# cs register map
Vendor: Texas Instruments
Peripheral module from a debugger description file (folder MSP432).
Registers are 32-bit, read-write, no defined reset value unless marked. A register's access mark holds for its fields unless they carry their own. Offsets are as the file gives them; lines under a group give offsets from that group; [hi:lo] are bit positions; {n}, {i} and the like mark numbered series; 'fields as' and 'values as' point back to an identical list; <NAME> marks a mode.

## CS
0x00 KEY
  [15:0] KEY — Write CSKEY = xxxx_695Ah to unlock CSCTL0, CSCTL1, CSCTL2, CSCT
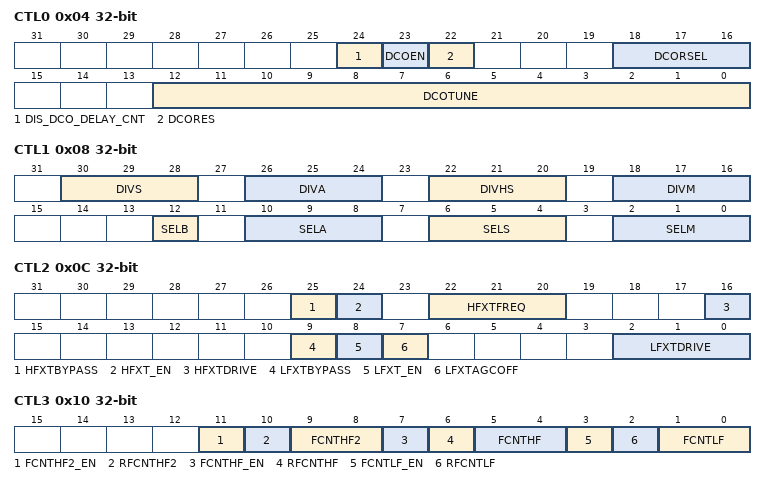
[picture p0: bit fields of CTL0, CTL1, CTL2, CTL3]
0x04 CTL0 — Control 0 Register
  [24] DIS_DCO_DELAY_CNT — Setting this bit disabes the DCO settling counter value
    0=DIS_DCO_DELAY_CNT__0 (DCO Settling delay counter is enabled); 1=DIS_DCO_DELAY_CNT__1 (DCO setlling delay counter disabled)
  [23] DCOEN — Enables the DCO oscillator regardless if used as a clock resour
    0=DCOEN__0 (DCO is on if it is used as a source for MCLK, HSMCLK , or SMCLK); 1=DCOEN__1 (DCO is on)
  [22] DCORES — Enables the DCO external resistor mode.
    0=DCORES__0 (Internal resistor mode); 1=DCORES__1 (External resistor mode)
  [18:16] DCORSEL — DCO frequency range select
    0=DCORSEL__0 (Nominal DCO Frequency Range (MHz): 1 to 2); 1=DCORSEL__1 (Nominal DCO Frequency Range (MHz): 2 to 4); 2=DCORSEL__2 (Nominal DCO Frequency Range (MHz): 4 to 8); 3=DCORSEL__3 (Nominal DCO Frequency Range (MHz): 8 to 16); 4=DCORSEL__4 (Nominal DCO Frequency Range (MHz): 16 to 32); 5=DCORSEL__5 (Nominal DCO Frequency Range (MHz): 32 to 64)
  [12:0] DCOTUNE — DCO frequency tuning select
0x08 CTL1 — Control 1 Register
  [30:28] DIVS — SMCLK source divider.
    0=DIVS__0 (f(SMCLK)/1); 1=DIVS__1 (f(SMCLK)/2); 2=DIVS__2 (f(SMCLK)/4); 3=DIVS__3 (f(SMCLK)/8); 4=DIVS__4 (f(SMCLK)/16); 5=DIVS__5 (f(SMCLK)/32); 6=DIVS__6 (f(SMCLK)/64); 7=DIVS__7 (f(SMCLK)/128)
  [26:24] DIVA — ACLK source divider.
    0=DIVA__0 (f(ACLK)/1); 1=DIVA__1 (f(ACLK)/2); 2=DIVA__2 (f(ACLK)/4); 3=DIVA__3 (f(ACLK)/8); 4=DIVA__4 (f(ACLK)/16); 5=DIVA__5 (f(ACLK)/32); 6=DIVA__6 (f(ACLK)/64); 7=DIVA__7 (f(ACLK)/128)
  [22:20] DIVHS — HSMCLK source divider.
    0=DIVHS__0 (f(HSMCLK)/1); 1=DIVHS__1 (f(HSMCLK)/2); 2=DIVHS__2 (f(HSMCLK)/4); 3=DIVHS__3 (f(HSMCLK)/8); 4=DIVHS__4 (f(HSMCLK)/16); 5=DIVHS__5 (f(HSMCLK)/32); 6=DIVHS__6 (f(HSMCLK)/64); 7=DIVHS__7 (f(HSMCLK)/128)
  [18:16] DIVM — MCLK source divider.
    0=DIVM__0 (f(MCLK)/1); 1=DIVM__1 (f(MCLK)/2); 2=DIVM__2 (f(MCLK)/4); 3=DIVM__3 (f(MCLK)/8); 4=DIVM__4 (f(MCLK)/16); 5=DIVM__5 (f(MCLK)/32); 6=DIVM__6 (f(MCLK)/64); 7=DIVM__7 (f(MCLK)/128)
  [12] SELB — Selects the BCLK source.
    0=SELB__0 (LFXTCLK); 1=SELB__1 (REFOCLK)
  [10:8] SELA — Selects the ACLK source.
    0=SELA__0 (when LFXT available, otherwise REFOCLK); 1=SELA__1; 2=SELA__2; {v}=SELA__{v} (for future use) (v=3..7)
  [6:4] SELS — Selects the SMCLK and HSMCLK source.
    0=SELS__0 (when LFXT available, otherwise REFOCLK); {v}=SELS__{v} (v=1..4); 5=SELS__5 (when HFXT available, otherwise DCOCLK); 6=SELS__6 (when HFXT2 available, otherwise DCOCLK); 7=SELS__7 (for furture use)
  [2:0] SELM — Selects the MCLK source.
    0=SELM__0 (when LFXT available, otherwise REFOCLK); {v}=SELM__{v} (v=1..4); 5=SELM__5 (when HFXT available, otherwise DCOCLK); 6=SELM__6 (when HFXT2 available, otherwise DCOCLK); 7=SELM__7 (for future use)
0x0C CTL2 — Control 2 Register
  [25] HFXTBYPASS — HFXT bypass select.
    0=HFXTBYPASS__0 (HFXT sourced by external crystal.); 1=HFXTBYPASS__1 (HFXT sourced by external square wave.)
  [24] HFXT_EN — Turns on the HFXT oscillator regardless if used as a clock reso
    0=HFXT_EN__0 (HFXT is on if it is used as a source for MCLK, HSMCLK , or SMCL); 1=HFXT_EN__1 (HFXT is on if HFXT is selected via the port selection and HFXT)
  [22:20] HFXTFREQ — The HFXT frequency selection
    0=HFXTFREQ__0 (1 MHz to 4 MHz); 1=HFXTFREQ__1 (>4 MHz to 8 MHz); 2=HFXTFREQ__2 (>8 MHz to 16 MHz); 3=HFXTFREQ__3 (>16 MHz to 24 MHz); 4=HFXTFREQ__4 (>24 MHz to 32 MHz); 5=HFXTFREQ__5 (>32 MHz to 40 MHz); 6=HFXTFREQ__6 (>40 MHz to 48 MHz)
  [16] HFXTDRIVE — HFXT oscillator drive selection
    0=HFXTDRIVE__0 (To be used for HFXTFREQ setting 000b); 1=HFXTDRIVE__1 (To be used for HFXTFREQ settings 001b to 111b)
  [9] LFXTBYPASS — LFXT bypass select.
    0=LFXTBYPASS__0 (LFXT sourced by external crystal.); 1=LFXTBYPASS__1 (LFXT sourced by external square wave.)
  [8] LFXT_EN — Turns on the LFXT oscillator regardless if used as a clock reso
    0=LFXT_EN__0 (LFXT is on if it is used as a source for ACLK, MCLK, HSMCLK , o); 1=LFXT_EN__1 (LFXT is on if LFXT is selected via the port selection and LFXT)
  [7] LFXTAGCOFF
    0=LFXTAGCOFF__0 (AGC enabled.); 1=LFXTAGCOFF__1 (AGC disabled.)
  [2:0] LFXTDRIVE — The LFXT oscillator current can be adjusted to its drive needs
    0=LFXTDRIVE__0 (Lowest current consumption.); {v}=LFXTDRIVE__{v} (Increased drive strength LFXT oscillator.) (v=1..6); 7=LFXTDRIVE__7 (Maximum drive strength LFXT oscillator.)
0x10 CTL3 — Control 3 Register
  [11] FCNTHF2_EN — Enable start fault counter for HFXT2
    0=FCNTHF2_EN__0 (Startup fault counter disabled. Counter is cleared.); 1=FCNTHF2_EN__1 (Startup fault counter enabled.)
  [10] RFCNTHF2 — Reset start fault counter for HFXT2
    0=RFCNTHF2__0 (Not applicable. Always reads as zero due to self clearing.); 1=RFCNTHF2__1 (Restarts the counter immediately.)
  [9:8] FCNTHF2 — Start flag counter for HFXT2
    0=FCNTHF2__0 (2048 cycles); 1=FCNTHF2__1 (4096 cycles); 2=FCNTHF2__2 (8192 cycles); 3=FCNTHF2__3 (16384 cycles)
  [7] FCNTHF_EN — Enable start fault counter for HFXT
    0=FCNTHF_EN__0 (Startup fault counter disabled. Counter is cleared.); 1=FCNTHF_EN__1 (Startup fault counter enabled.)
  [6] RFCNTHF — Reset start fault counter for HFXT
    0=RFCNTHF__0 (Not applicable. Always reads as zero due to self clearing.); 1=RFCNTHF__1 (Restarts the counter immediately.)
  [5:4] FCNTHF — Start flag counter for HFXT
    0=FCNTHF__0 (2048 cycles); 1=FCNTHF__1 (4096 cycles); 2=FCNTHF__2 (8192 cycles); 3=FCNTHF__3 (16384 cycles)
  [3] FCNTLF_EN — Enable start fault counter for LFXT
    0=FCNTLF_EN__0 (Startup fault counter disabled. Counter is cleared.); 1=FCNTLF_EN__1 (Startup fault counter enabled.)
  [2] RFCNTLF — Reset start fault counter for LFXT
    0=RFCNTLF__0 (Not applicable. Always reads as zero due to self clearing.); 1=RFCNTLF__1 (Restarts the counter immediately.)
  [1:0] FCNTLF — Start flag counter for LFXT
    0=FCNTLF__0 (4096 cycles); 1=FCNTLF__1 (8192 cycles); 2=FCNTLF__2 (16384 cycles); 3=FCNTLF__3 (32768 cycles)
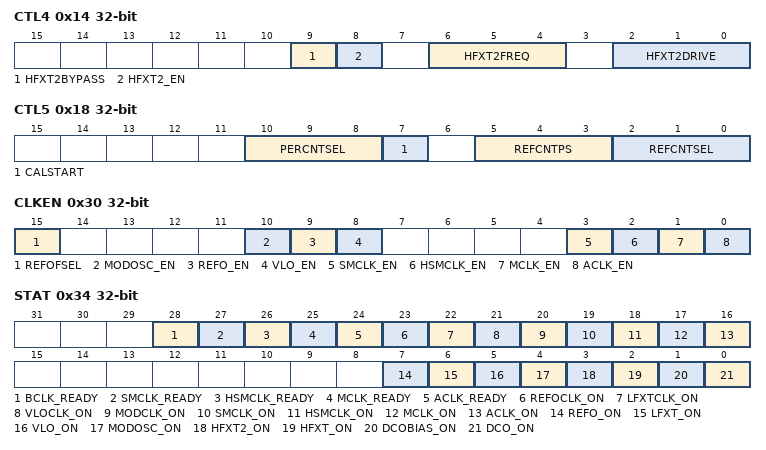
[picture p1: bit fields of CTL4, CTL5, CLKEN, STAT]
0x14 CTL4 — Control 4 Register
  [9] HFXT2BYPASS — HFXT2 bypass select
  [8] HFXT2_EN — Turns on the HFXT2 oscillator regardless if used as a clock res
  [6:4] HFXT2FREQ — The HFXT2 frequency selection
  [2:0] HFXT2DRIVE — The HFXT2 oscillator current can be adjusted to its drive needs
    0=HFXT2DRIVE__0 (Lowest current consumption); {v}=HFXT2DRIVE__{v} (Increased drive strength HFXT2 oscillator) (v=1..6); 7=HFXT2DRIVE__7 (Maximum drive strength HFXT2 oscillator)
0x18 CTL5 — Control 5 Register
  [10:8] PERCNTSEL — Period counter source select
  [7] CALSTART — Start clock calibration counters
  [5:3] REFCNTPS — Reference clock prescaler 000b = /1 001b = /16 010b = /32 0
  [2:0] REFCNTSEL — Reference counter source select
0x1C CTL6 — Control 6 Register
  [15:0] PERCNT — Calibration period counter. Read only.
0x20 CTL7 — Control 7 Register
  [15:0] REFCNT — Calibration reference period counter.
0x30 CLKEN — Clock Enable Register
  [15] REFOFSEL — Selects REFO nominal frequency.
    0=REFOFSEL__0 (32 kHz); 1=REFOFSEL__1 (128 kHz)
  [10] MODOSC_EN — Turns on the MODOSC oscillator regardless if used as a clock re
    0=MODOSC_EN__0 (MODOSC is on only if it is used as a source for ACLK, MCLK, HSM); 1=MODOSC_EN__1 (MODOSC is on)
  [9] REFO_EN — Turns on the REFO oscillator regardless if used as a clock reso
    0=REFO_EN__0 (REFO is on only if it is used as a source for ACLK, MCLK, HSMCL); 1=REFO_EN__1 (REFO is on)
  [8] VLO_EN — Turns on the VLO oscillator regardless if used as a clock resou
    0=VLO_EN__0 (VLO is on only if it is used as a source for ACLK, MCLK, HSMCLK); 1=VLO_EN__1 (VLO is on)
  [3] SMCLK_EN — SMCLK system clock conditional request enable.
    0=SMCLK_EN__0 (SMCLK disabled regardless of conditional clock requests.); 1=SMCLK_EN__1 (SMCLK enabled based on any conditional clock requests)
  [2] HSMCLK_EN — HSMCLK system clock conditional request enable.
    0=HSMCLK_EN__0 (HSMCLK disabled regardless of conditional clock requests); 1=HSMCLK_EN__1 (HSMCLK enabled based on any conditional clock requests)
  [1] MCLK_EN — MCLK system clock conditional request enable
    0=MCLK_EN__0 (MCLK disabled regardless of conditional clock requests); 1=MCLK_EN__1 (MCLK enabled based on any conditional clock requests)
  [0] ACLK_EN — ACLK system clock conditional request enable.
    0=ACLK_EN__0 (ACLK disabled regardless of conditional clock requests); 1=ACLK_EN__1 (ACLK enabled based on any conditional clock requests)
0x34 STAT — Status Register
  [28] BCLK_READY — BCLK Ready status
    0=BCLK_READY__0 (Not ready); 1=BCLK_READY__1 (Ready)
  [27] SMCLK_READY — SMCLK Ready status
    0=SMCLK_READY__0 (Not ready); 1=SMCLK_READY__1 (Ready)
  [26] HSMCLK_READY — HSMCLK Ready status
    0=HSMCLK_READY__0 (Not ready); 1=HSMCLK_READY__1 (Ready)
  [25] MCLK_READY — MCLK Ready status
    0=MCLK_READY__0 (Not ready); 1=MCLK_READY__1 (Ready)
  [24] ACLK_READY — ACLK Ready status
    0=ACLK_READY__0 (Not ready); 1=ACLK_READY__1 (Ready)
  [23] REFOCLK_ON — REFOCLK system clock status
    0=REFOCLK_ON__0 (Inactive); 1=REFOCLK_ON__1 (Active)
  [22] LFXTCLK_ON — LFXTCLK system clock status
    0=LFXTCLK_ON__0 (Inactive); 1=LFXTCLK_ON__1 (Active)
  [21] VLOCLK_ON — VLOCLK system clock status
    0=VLOCLK_ON__0 (Inactive); 1=VLOCLK_ON__1 (Active)
  [20] MODCLK_ON — MODCLK system clock status
    0=MODCLK_ON__0 (Inactive); 1=MODCLK_ON__1 (Active)
  [19] SMCLK_ON — SMCLK system clock status
    0=SMCLK_ON__0 (Inactive); 1=SMCLK_ON__1 (Active)
  [18] HSMCLK_ON — HSMCLK system clock status
    0=HSMCLK_ON__0 (Inactive); 1=HSMCLK_ON__1 (Active)
  [17] MCLK_ON — MCLK system clock status
    0=MCLK_ON__0 (Inactive); 1=MCLK_ON__1 (Active)
  [16] ACLK_ON — ACLK system clock status
    0=ACLK_ON__0 (Inactive); 1=ACLK_ON__1 (Active)
  [7] REFO_ON — REFO status
    0=REFO_ON__0 (Inactive); 1=REFO_ON__1 (Active)
  [6] LFXT_ON — LFXT status. Only available on devices with LFXT.
    0=LFXT_ON__0 (Inactive); 1=LFXT_ON__1 (Active)
  [5] VLO_ON — VLO status
    0=VLO_ON__0 (Inactive); 1=VLO_ON__1 (Active)
  [4] MODOSC_ON — MODOSC status
    0=MODOSC_ON__0 (Inactive); 1=MODOSC_ON__1 (Active)
  [3] HFXT2_ON — HFXT2 status. Only available on devices with HFXT2.
    0=HFXT2_ON__0 (Inactive); 1=HFXT2_ON__1 (Active)
  [2] HFXT_ON — HFXT status. Only available on devices with HFXT.
    0=HFXT_ON__0 (Inactive); 1=HFXT_ON__1 (Active)
  [1] DCOBIAS_ON — DCO bias status
    0=DCOBIAS_ON__0 (Inactive); 1=DCOBIAS_ON__1 (Active)
  [0] DCO_ON — DCO status
    0=DCO_ON__0 (Inactive); 1=DCO_ON__1 (Active)
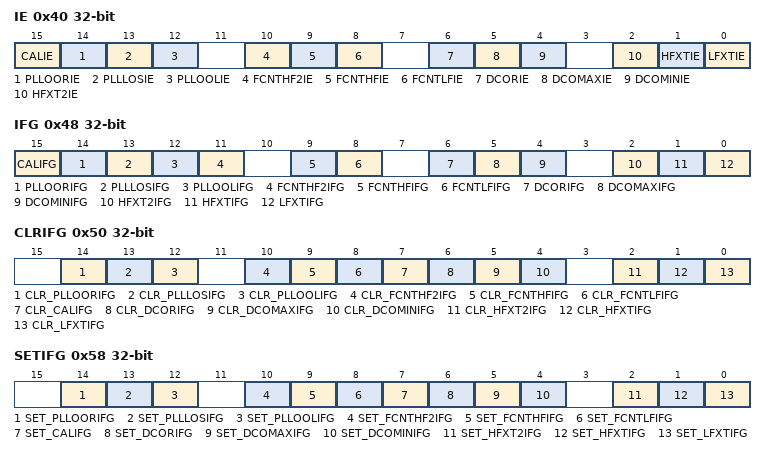
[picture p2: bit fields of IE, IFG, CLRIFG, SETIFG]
0x40 IE — Interrupt Enable Register
  [15] CALIE — REFCNT period counter interrupt enable.
    0=CALIE__0 (Interrupt disabled); 1=CALIE__1 (Interrupt enabled)
  [14] PLLOORIE — PLL out-of-range interrupt enable
    0=PLLOORIE__0 (Interrupt disabled); 1=PLLOORIE__1 (Interrupt enabled)
  [13] PLLLOSIE — PLL loss-of-signal interrupt enable
    0=PLLLOSIE__0 (Interrupt disabled); 1=PLLLOSIE__1 (Interrupt enabled)
  [12] PLLOOLIE — PLL out-of-lock interrupt enable
    0=PLLOOLIE__0 (Interrupt disabled); 1=PLLOOLIE__1 (Interrupt enabled)
  [10] FCNTHF2IE — Start fault counter interrupt enable HFXT2
    0=FCNTHF2IE__0 (Interrupt disabled); 1=FCNTHF2IE__1 (Interrupt enabled)
  [9] FCNTHFIE — Start fault counter interrupt enable HFXT
    0=FCNTHFIE__0 (Interrupt disabled); 1=FCNTHFIE__1 (Interrupt enabled)
  [8] FCNTLFIE — Start fault counter interrupt enable LFXT
    0=FCNTLFIE__0 (Interrupt disabled); 1=FCNTLFIE__1 (Interrupt enabled)
  [6] DCORIE — DCO external resistor fault flag interrupt enable.
    0=DCORIE__0 (Interrupt disabled); 1=DCORIE__1 (Interrupt enabled)
  [5] DCOMAXIE — DCO maximum fault flag interrupt enable.
    0=DCOMAXIE__0 (Interrupt disabled); 1=DCOMAXIE__1 (Interrupt enabled)
  [4] DCOMINIE — DCO minimum fault flag interrupt enable.
    0=DCOMINIE__0 (Interrupt disabled); 1=DCOMINIE__1 (Interrupt enabled)
  [2] HFXT2IE — HFXT2 oscillator fault flag interrupt enable
    0=HFXT2IE__0 (Interrupt disabled); 1=HFXT2IE__1 (Interrupt enabled)
  [1] HFXTIE — HFXT oscillator fault flag interrupt enable
    0=HFXTIE__0 (Interrupt disabled); 1=HFXTIE__1 (Interrupt enabled)
  [0] LFXTIE — LFXT oscillator fault flag interrupt enable
    0=LFXTIE__0 (Interrupt disabled); 1=LFXTIE__1 (Interrupt enabled)
0x48 IFG — Interrupt Flag Register
  [15] CALIFG — REFCNT period counter expired
    0=CALIFG__0 (REFCNT period counter not expired); 1=CALIFG__1 (REFCNT period counter expired)
  [14] PLLOORIFG — PLL out-of-range interrupt flag
    0=PLLOORIFG__0 (No interrupt pending); 1=PLLOORIFG__1 (Interrupt pending)
  [13] PLLLOSIFG — PLL loss-of-signal interrupt flag
    0=PLLLOSIFG__0 (No interrupt pending); 1=PLLLOSIFG__1 (Interrupt pending)
  [12] PLLOOLIFG — PLL out-of-lock interrupt flag
    0=PLLOOLIFG__0 (No interrupt pending); 1=PLLOOLIFG__1 (Interrupt pending)
  [11] FCNTHF2IFG — Start fault counter interrupt flag HFXT2
    0=FCNTHF2IFG__0 (Start counter not expired); 1=FCNTHF2IFG__1 (Start counter expired)
  [9] FCNTHFIFG — Start fault counter interrupt flag HFXT
    0=FCNTHFIFG__0 (Start counter not expired); 1=FCNTHFIFG__1 (Start counter expired)
  [8] FCNTLFIFG — Start fault counter interrupt flag LFXT
    0=FCNTLFIFG__0 (Start counter not expired); 1=FCNTLFIFG__1 (Start counter expired)
  [6] DCORIFG — DCO external resistor fault flag
    0=DCORIFG__0 (DCO external resistor present); 1=DCORIFG__1 (DCO external resistor fault)
  [5] DCOMAXIFG — DCO maximum fault flag
    0=DCOMAXIFG__0 (DCO frequency not at maximum setting of the current DCORSEL set); 1=DCOMAXIFG__1 (DCO frequency at maximum setting of the current DCORSEL setting)
  [4] DCOMINIFG — DCO minimum fault flag
    0=DCOMINIFG__0 (DCO frequency not at minimum setting of the current DCORSEL set); 1=DCOMINIFG__1 (DCO frequency at minimum setting of the current DCORSEL setting)
  [2] HFXT2IFG — HFXT2 oscillator fault flag
    0=HFXT2IFG__0 (No fault condition occurred after the last reset); 1=HFXT2IFG__1 (HFXT2 fault. A HFXT2 fault occurred after the last reset)
  [1] HFXTIFG — HFXT oscillator fault flag
    0=HFXTIFG__0 (No fault condition occurred after the last reset); 1=HFXTIFG__1 (HFXT fault. A HFXT fault occurred after the last reset)
  [0] LFXTIFG — LFXT oscillator fault flag
    0=LFXTIFG__0 (No fault condition occurred after the last reset); 1=LFXTIFG__1 (LFXT fault. A LFXT fault occurred after the last reset)
0x50 CLRIFG — Clear Interrupt Flag Register
  [14] CLR_PLLOORIFG — PLL out-of-range clear interrupt flag
    0=CLR_PLLOORIFG__0 (No effect); 1=CLR_PLLOORIFG__1 (Clear pending interrupt flag)
  [13] CLR_PLLLOSIFG — PLL loss-of-signal clear interrupt flag
    0=CLR_PLLLOSIFG__0 (No effect); 1=CLR_PLLLOSIFG__1 (Clear pending interrupt flag)
  [12] CLR_PLLOOLIFG — PLL out-of-lock clear interrupt flag
    0=CLR_PLLOOLIFG__0 (No effect); 1=CLR_PLLOOLIFG__1 (Clear pending interrupt flag)
  [10] CLR_FCNTHF2IFG — Start fault counter clear interrupt flag HFXT2
    0=CLR_FCNTHF2IFG__0 (No effect); 1=CLR_FCNTHF2IFG__1 (Clear pending interrupt flag)
  [9] CLR_FCNTHFIFG — Start fault counter clear interrupt flag HFXT
    0=CLR_FCNTHFIFG__0 (No effect); 1=CLR_FCNTHFIFG__1 (Clear pending interrupt flag)
  [8] CLR_FCNTLFIFG — Start fault counter clear interrupt flag LFXT
    0=CLR_FCNTLFIFG__0 (No effect); 1=CLR_FCNTLFIFG__1 (Clear pending interrupt flag)
  [7] CLR_CALIFG — REFCNT period counter clear interrupt flag
    0=CLR_CALIFG__0 (No effect); 1=CLR_CALIFG__1 (Clear pending interrupt flag)
  [6] CLR_DCORIFG — Clear DCO external resistor fault interrupt flag
    0=CLR_DCORIFG__0 (No effect); 1=CLR_DCORIFG__1 (Clear pending interrupt flag)
  [5] CLR_DCOMAXIFG — Clear DCO maximum fault interrupt flag. Does not clear OFIFG.
    0=CLR_DCOMAXIFG__0 (No effect); 1=CLR_DCOMAXIFG__1 (Clear pending interrupt flag)
  [4] CLR_DCOMINIFG — Clear DCO minimum fault interrupt flag. Does not clear OFIFG.
    0=CLR_DCOMINIFG__0 (No effect); 1=CLR_DCOMINIFG__1 (Clear pending interrupt flag)
  [2] CLR_HFXT2IFG — Clear HFXT2 oscillator fault interrupt flag
    0=CLR_HFXT2IFG__0 (No effect); 1=CLR_HFXT2IFG__1 (Clear pending interrupt flag)
  [1] CLR_HFXTIFG — Clear HFXT oscillator fault interrupt flag
    0=CLR_HFXTIFG__0 (No effect); 1=CLR_HFXTIFG__1 (Clear pending interrupt flag)
  [0] CLR_LFXTIFG — Clear LFXT oscillator fault interrupt flag
    0=CLR_LFXTIFG__0 (No effect); 1=CLR_LFXTIFG__1 (Clear pending interrupt flag)
0x58 SETIFG — Set Interrupt Flag Register
  [14] SET_PLLOORIFG — NOTE: This bit is reserved for PLL implementations
    0=SET_PLLOORIFG__0 (No effect); 1=SET_PLLOORIFG__1 (Set pending interrupt flag)
  [13] SET_PLLLOSIFG — NOTE: This bit is reserved for PLL implementations
    0=SET_PLLLOSIFG__0 (No effect); 1=SET_PLLLOSIFG__1 (Set pending interrupt flag)
  [12] SET_PLLOOLIFG — NOTE: This bit is reserved for PLL implementations
    0=SET_PLLOOLIFG__0 (No effect); 1=SET_PLLOOLIFG__1 (Set pending interrupt flag)
  [10] SET_FCNTHF2IFG — NOTE: This bit is reserved for HFXT2 implementations
    0=SET_FCNTHF2IFG__0 (No effect); 1=SET_FCNTHF2IFG__1 (Set pending interrupt flag)
  [9] SET_FCNTHFIFG — Start fault counter set interrupt flag HFXT
    0=SET_FCNTHFIFG__0 (No effect); 1=SET_FCNTHFIFG__1 (Set pending interrupt flag)
  [8] SET_FCNTLFIFG — Start fault counter set interrupt flag LFXT
    0=SET_FCNTLFIFG__0 (No effect); 1=SET_FCNTLFIFG__1 (Set pending interrupt flag)
  [7] SET_CALIFG — REFCNT period counter set interrupt flag. expired.
    0=SET_CALIFG__0 (No effect); 1=SET_CALIFG__1 (Set pending interrupt flag)
  [6] SET_DCORIFG — Set DCO external resistor fault interrupt flag.
    0=SET_DCORIFG__0 (No effect); 1=SET_DCORIFG__1 (Set pending interrupt flag)
  [5] SET_DCOMAXIFG — Set DCO maximum fault interrupt flag.
    0=SET_DCOMAXIFG__0 (No effect); 1=SET_DCOMAXIFG__1 (Set pending interrupt flag)
  [4] SET_DCOMINIFG — Set DCO minimum fault interrupt flag.
    0=SET_DCOMINIFG__0 (No effect); 1=SET_DCOMINIFG__1 (Set pending interrupt flag)
  [2] SET_HFXT2IFG — Set HFXT2 oscillator fault interrupt flag
    0=SET_HFXT2IFG__0 (No effect); 1=SET_HFXT2IFG__1 (Set pending interrupt flag)
  [1] SET_HFXTIFG — Set HFXT oscillator fault interrupt flag
    0=SET_HFXTIFG__0 (No effect); 1=SET_HFXTIFG__1 (Set pending interrupt flag)
  [0] SET_LFXTIFG — Set LFXT oscillator fault interrupt flag
    0=SET_LFXTIFG__0 (No effect); 1=SET_LFXTIFG__1 (Set pending interrupt flag)
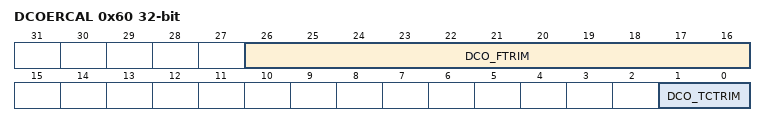
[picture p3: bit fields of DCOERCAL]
0x60 DCOERCAL — DCO external resistor cailbration register
  [26:16] DCO_FTRIM — DCO frequency trim
  [1:0] DCO_TCTRIM — DCO Temperature compensation Trim
